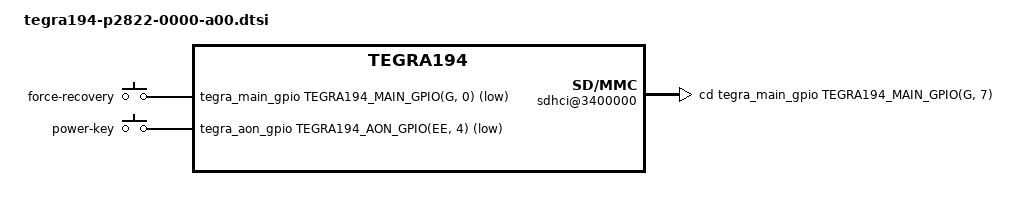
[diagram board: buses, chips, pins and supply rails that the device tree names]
/*
 * Copyright (c) 2017-2020, NVIDIA CORPORATION.  All rights reserved.
 *
 * This program is free software; you can redistribute it and/or modify it
 * under the terms and conditions of the GNU General Public License,
 * version 2, as published by the Free Software Foundation.
 *
 * This program is distributed in the hope it will be useful, but WITHOUT
 * ANY WARRANTY; without even the implied warranty of MERCHANTABILITY or
 * FITNESS FOR A PARTICULAR PURPOSE.  See the GNU General Public License for
 * more details.
 *
 * You should have received a copy of the GNU General Public License
 * along with this program.  If not, see <http://www.gnu.org/licenses/>.
 */

#include <t19x-common-modules/tegra194-cvb-p2822-0000-a00.dtsi>
#include <dt-bindings/gpio/tegra194-gpio.h>
#include "dt-bindings/input/input.h"
#include "tegra194-p2822-disp.dtsi"

/ {
	sdhci@3400000 {
		mmc-ocr-mask = <0x0>;
		cd-gpios = <&tegra_main_gpio TEGRA194_MAIN_GPIO(G, 7) 0>;
		nvidia,cd-wakeup-capable;
		nvidia,vmmc-always-on;
		status = "okay";
	};

	gpio-keys {
		compatible = "gpio-keys";
		gpio-keys,name = "gpio-keys";

		forcerecovery {
			label = "force-recovery";
			gpios = <&tegra_main_gpio TEGRA194_MAIN_GPIO(G, 0) GPIO_ACTIVE_LOW>;
			linux,code = <BTN_1>;
		};

		power_key {
			label = "power-key";
			gpios = <&tegra_aon_gpio TEGRA194_AON_GPIO(EE, 4) GPIO_ACTIVE_LOW>;
			linux,code = <KEY_POWER>;
			gpio-key,wakeup;
		};
	};

	gte@c1e0000 {
		status = "okay";
	};

	gpio@c2f0000 {
		/delete-property/ use-timestamp;
	};
};
